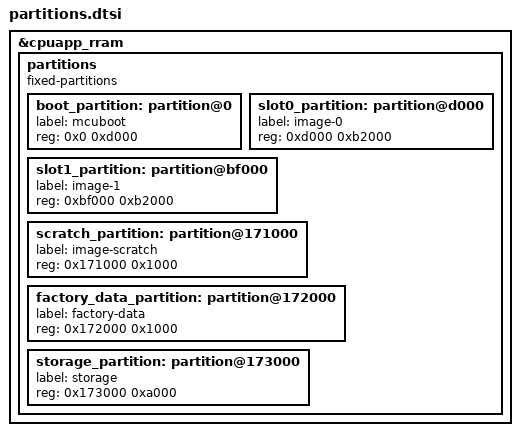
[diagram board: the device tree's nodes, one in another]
&cpuapp_rram {
        /* Delete the default board partitions, prevents label collisions */
        /delete-node/ partitions;

        partitions {
                compatible = "fixed-partitions";
                #address-cells = <1>;
                #size-cells = <1>;

                boot_partition: partition@0 {
                        label = "mcuboot";
                        reg = <0x0 0xd000>;
                };

                slot0_partition: partition@d000 {
                        label = "image-0";
                        reg = <0xd000 0xb2000>;
                };

                slot1_partition: partition@bf000 {
                        label = "image-1";
                        reg = <0xbf000 0xb2000>;
                };

                scratch_partition: partition@171000 {
                        label = "image-scratch";
                        reg = <0x171000 0x1000>;
                };

                factory_data_partition: partition@172000 {
                        label = "factory-data";
                        reg = <0x172000 0x1000>;
                };

                storage_partition: partition@173000 {
                        label = "storage";
                        reg = <0x173000 0xa000>;
                };
        };
};
